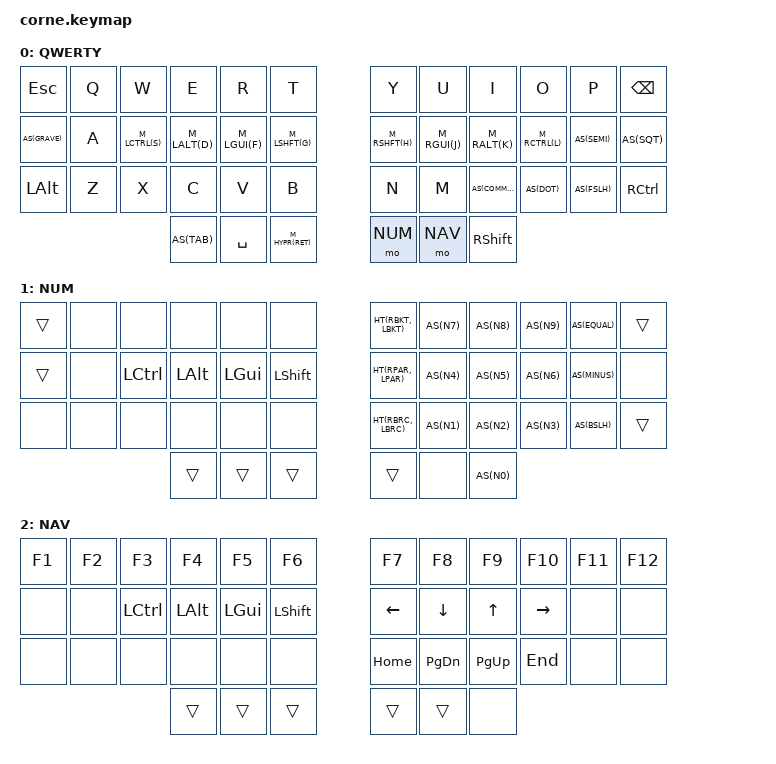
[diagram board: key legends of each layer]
/*
 * Copyright (c) 2020 The ZMK Contributors
 *
 * SPDX-License-Identifier: MIT
 */

#include <behaviors.dtsi>
#include <dt-bindings/zmk/keys.h>
#include <dt-bindings/zmk/bt.h>

#define BASE 0
#define NUM 1
#define NAV 2

#define AS(keycode) &ht LS(keycode) keycode
#define HT(tap, hold) &ht tap hold
#define M_LGUI(keycode) &hm LGUI keycode
#define M_RGUI(keycode) &hm RGUI keycode
#define M_LALT(keycode) &hm LALT keycode
#define M_RALT(keycode) &hm RALT keycode
#define M_LSHFT(keycode) &hm LSHFT keycode
#define M_RSHFT(keycode) &hm RSHFT keycode
#define M_LCTRL(keycode) &hm LCTRL keycode
#define M_RCTRL(keycode) &hm RCTRL keycode
#define M_HYPR(keycode) &hm CAPS keycode // CAPS is HYPER in Hyperkey app

/ {
        behaviors {
                ht: hold_tap {
                        compatible = "zmk,behavior-hold-tap";
                        #binding-cells = <2>;
                        tapping_term_ms = <150>;
                        quick_tap_ms = <0>;
                        flavor = "tap-preferred";
                        bindings = <&kp>, <&kp>;
                };

                hm: homerow_mods {
                        compatible = "zmk,behavior-hold-tap";
                        #binding-cells = <2>;
                        tapping-term-ms = <250>;
                        quick-tap-ms = <0>;
                        flavor = "balanced";
                        require-prior-idle-ms = <250>;
                        bindings = <&kp>, <&kp>;
                };
        };

        keymap {
                compatible = "zmk,keymap";
                base_layer {
                        display-name = "QWERTY";
                        bindings = <
                                &kp ESC   &kp Q &kp W      &kp E     &kp R     &kp T           &kp Y      &kp U     &kp I     &kp O      &kp P    &kp BSPC
                                AS(GRAVE) &kp A M_LCTRL(S) M_LALT(D) M_LGUI(F) M_LSHFT(G)      M_RSHFT(H) M_RGUI(J) M_RALT(K) M_RCTRL(L) AS(SEMI) AS(SQT)
                                &kp LALT  &kp Z &kp X      &kp C     &kp V     &kp B           &kp N      &kp M     AS(COMMA) AS(DOT)    AS(FSLH) &kp RCTRL
                                                           AS(TAB)   &kp SPACE M_HYPR(RET)     &mo NUM    &mo NAV   &kp RSHFT
                        >;
                };

                num_layer {
                        display-name = "NUM";
                        bindings = <
                                &trans &none &none     &none    &none    &none     HT(RBKT, LBKT) AS(N7) AS(N8) AS(N9) AS(EQUAL) &trans
                                &trans &none &kp LCTRL &kp LALT &kp LGUI &kp LSHFT HT(RPAR, LPAR) AS(N4) AS(N5) AS(N6) AS(MINUS) &none
                                &none  &none &none     &none    &none    &none     HT(RBRC, LBRC) AS(N1) AS(N2) AS(N3) AS(BSLH)  &trans
                                                       &trans   &trans   &trans    &trans         &none  AS(N0)
                        >;
                };

                nav_layer {
                        display-name = "NAV";
                        bindings = <
                                &kp F1 &kp F2 &kp F3    &kp F4   &kp F5   &kp F6     &kp F7   &kp F8    &kp F9    &kp F10   &kp F11 &kp F12
                                &none  &none  &kp LCTRL &kp LALT &kp LGUI &kp LSHFT  &kp LEFT &kp DOWN  &kp UP    &kp RIGHT &none   &none
                                &none  &none  &none     &none    &none    &none      &kp HOME &kp PG_DN &kp PG_UP &kp END   &none   &none
                                                        &trans   &trans   &trans     &trans   &trans    &none
                        >;
                };
        };
};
